# f2838x_cm_aes_regs register map
Vendor: Texas Instruments
Peripheral module from a debugger description file (folder C2000).
Address unit: 16 bits
Registers are 32-bit, read-write, no defined reset value unless marked. A register's access mark holds for its fields unless they carry their own. Offsets are as the file gives them; lines under a group give offsets from that group; [hi:lo] are bit positions; {n}, {i} and the like mark numbered series; 'fields as' and 'values as' point back to an identical list; <NAME> marks a mode.

## AES_REGS — AES Registers
0x00 AES_KEY2_6 — XTS Second Key or CBC-MAC Third Key
  [31:0] KEY — AES_KEY2[223:192] / AES_KEY3[95:64]
0x04 AES_KEY2_7 — XTS Second Key or CBC-MAC Third Key
  [31:0] KEY — AES_KEY2[255:224] / AES_KEY3[127:96]
0x08 AES_KEY2_4 — XTS/CCM Second Key or CBC-MAC Third Key
  [31:0] KEY — AES_KEY2[159:128] / AES_KEY3[31:0]
0x0C AES_KEY2_5 — XTS Second Key or CBC-MAC Third Key
  [31:0] KEY — AES_KEY2[191:160] / AES_KEY3[63:32]
0x10 AES_KEY2_2 — XTS/CCM/CBC-MAC Second Key or Hash Key Input
  [31:0] KEY — AES_KEY2/AES_GHASH_H[95:64]
0x14 AES_KEY2_3 — XTS/CCM/CBC-MAC Second Key or Hash Key Input
  [31:0] KEY — AES_KEY2/AES_GHASH_H[127:96]
0x18 AES_KEY2_0 — XTS/CCM/CBC-MAC Second Key or Hash Key Input
  [31:0] KEY — AES_KEY2/AES_GHASH_H[31:0]
0x1C AES_KEY2_1 — XTS/CCM/CBC-MAC Second Key or Hash Key Input
  [31:0] KEY — AES_KEY2/AES_GHASH_H[63:32]
0x20 AES_KEY1_6 — Key
  [31:0] KEY — Key Data
0x24 AES_KEY1_7 — Key
  [31:0] KEY — Key Data
0x28 AES_KEY1_4 — Key
  [31:0] KEY — Key Data
0x2C AES_KEY1_5 — Key
  [31:0] KEY — Key Data
0x30 AES_KEY1_2 — Key
  [31:0] KEY — Key Data
0x34 AES_KEY1_3 — Key
  [31:0] KEY — Key Data
0x38 AES_KEY1_0 — Key
  [31:0] KEY — Key Data
0x3C AES_KEY1_1 — Key
  [31:0] KEY — Key Data
{0x40+4i} AES_IV_IN_OUT_{i} (i=0..3) — Initialization Vector {i}
  [31:0] DATA — Initialization Vector Input
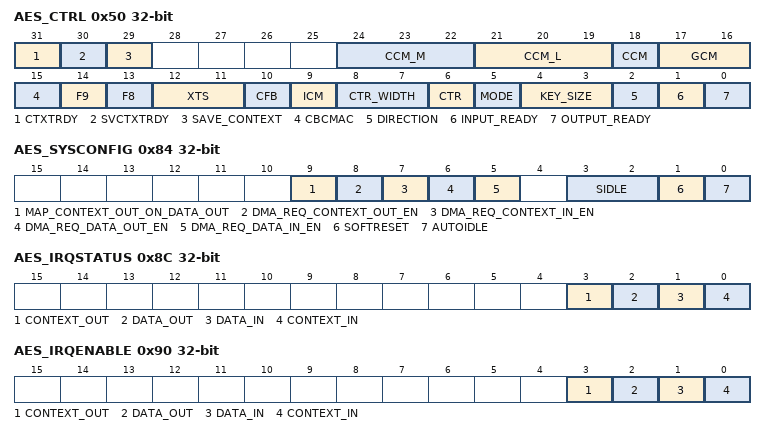
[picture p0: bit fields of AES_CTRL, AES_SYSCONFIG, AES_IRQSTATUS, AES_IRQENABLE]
0x50 AES_CTRL access per field — Input/Output Buffer Control and Mode Selection
  [31] CTXTRDY ro — Context Data Registers Ready
  [30] SVCTXTRDY ro — AES TAG/IV Block(s) Ready
  [29] SAVE_CONTEXT rw — TAG or Result IV Save
  [24:22] CCM_M rw — Length of the authentication field for CCM operations
  [21:19] CCM_L rw — Width of the length field for CCM operations
  [18] CCM rw — AES-CCM Mode Enable
  [17:16] GCM rw — AES-GCM Mode Enable
  [15] CBCMAC rw — AES-CBC MAC Enable
  [14] F9 rw — AES f9 Mode Enable
  [13] F8 rw — AES f8 Mode Enable
  [12:11] XTS rw — AES-XTS Operation Enable
  [10] CFB rw — Full block AES cipher feedback mode (CFB128) Enable
  [9] ICM rw — AES Integer Counter Mode (ICM) Enable
  [8:7] CTR_WIDTH rw — AES-CTR Mode Counter Width
  [6] CTR rw — Counter Mode
  [5] MODE rw — ECB/CBC Mode
  [4:3] KEY_SIZE rw
  [2] DIRECTION rw — Encryption/Decryption Selection
  [1] INPUT_READY ro — Input Ready Status
  [0] OUTPUT_READY ro — Output Ready Status
0x54 AES_C_LENGTH_0 — Crypto Data Length 0
  [31:0] LENGTH — Cryptographic data length in bytes
0x58 AES_C_LENGTH_1 — Crypto Data Length 1
  [31:0] LENGTH — Cryptographic data length in bytes for all modes.
0x5C AES_AUTH_LENGTH — AAD Data Length
  [31:0] AUTH — Authentication Data Length
{0x60+4i} AES_DATA_IN_OUT_{i} (i=0..3) — Data Word {i}
  [31:0] DATA — Secure Data RW
{0x70+4i} AES_TAG_OUT_{i} ro (i=0..3) — Hash Result {i}
  [31:0] HASH — Hash Result
0x80 AES_REV ro — Module Revision Number
  [31:0] REVISION — Revision number
0x84 AES_SYSCONFIG — System Configuration
  [9] MAP_CONTEXT_OUT_ON_DATA_OUT — Map Context Out on Data Out Enable
  [8] DMA_REQ_CONTEXT_OUT_EN — DMA Request Context Out Enable
  [7] DMA_REQ_CONTEXT_IN_EN — DMA Request Context In Enable
  [6] DMA_REQ_DATA_OUT_EN — DMA Request Data Out Enable
  [5] DMA_REQ_DATA_IN_EN — DMA Request Data In Enable
  [3:2] SIDLE — Slave Idle Mode
  [1] SOFTRESET
  [0] AUTOIDLE
0x88 AES_SYSSTATUS ro — Reset Status
  [0] RESETDONE
0x8C AES_IRQSTATUS ro — Interrupt Status
  [3] CONTEXT_OUT — Context Output Interrupt Status
  [2] DATA_OUT — Data Out Interrupt Status
  [1] DATA_IN — Data In Interrupt Status
  [0] CONTEXT_IN — Context In Interrupt Status
0x90 AES_IRQENABLE — Interrupt Enable
  [3] CONTEXT_OUT — Context Out Interrupt Enable
  [2] DATA_OUT — Data Out Interrupt Enable
  [1] DATA_IN — Data In Interrupt Enable
  [0] CONTEXT_IN — Context In Interrupt Enable
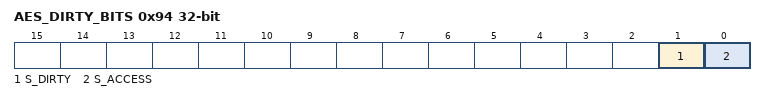
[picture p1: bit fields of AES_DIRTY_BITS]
0x94 AES_DIRTY_BITS — Accessed / Dirty Bits
  [1] S_DIRTY — AES Dirty Bit
  [0] S_ACCESS — AES Access Bit
